AUTOSAR XML (schema 4-2-1)
package /ECUCompositionTypes
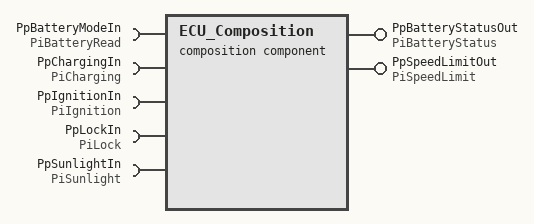
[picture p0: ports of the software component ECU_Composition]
  composition sw component type ECU_Composition
    provide port PpBatteryStatusOut: nonqueued-sender-com-spec=data-element=DeBatteryStatus, provided-interface=PiBatteryStatus
    provide port PpSpeedLimitOut: nonqueued-sender-com-spec=data-element=DeSpeedLimit, provided-interface=PiSpeedLimit
    5 x require port:
      PpBatteryModeIn: required-interface=PiBatteryRead
      PpChargingIn: nonqueued-receiver-com-spec{data-element=DeCharging, filter=data-filter-type=ALWAYS}, required-interface=PiCharging
      PpIgnitionIn: nonqueued-receiver-com-spec{data-element=DeIgnition, filter=data-filter-type=ALWAYS}, required-interface=PiIgnition
      PpLockIn: nonqueued-receiver-com-spec{data-element=DeLock, filter=data-filter-type=ALWAYS}, required-interface=PiLock
      PpSunlightIn: nonqueued-receiver-com-spec{data-element=DeSunlight, filter=data-filter-type=ALWAYS}, required-interface=PiSunlight
    component CpCoApplication: type=CtCoApplication
    delegate CpCoApplication.PpBatteryModeIn <-> outer port PpBatteryModeIn
    delegate CpCoApplication.PpBatteryStatusOut <-> outer port PpBatteryStatusOut
    delegate CpCoApplication.PpChargingIn <-> outer port PpChargingIn
    delegate CpCoApplication.PpIgnitionIn <-> outer port PpIgnitionIn
    delegate CpCoApplication.PpLockIn <-> outer port PpLockIn
    delegate CpCoApplication.PpSpeedLimitOut <-> outer port PpSpeedLimitOut
    delegate CpCoApplication.PpSunlightIn <-> outer port PpSunlightIn
package /EndToEndProtections
  end to end protection set EndToEndConnections
package /VehicleProject
  system System: category=SYSTEM_EXTRACT
    system mapping System_MPPNG
      data-mappings:
        data-element=ECU_Composition.PpLockIn.DeLock, system-signal=sig_Locking
        data-element=ECU_Composition.PpChargingIn.DeCharging, system-signal=sig_SolarPanelSwitch
        data-element=ECU_Composition.PpSunlightIn.DeSunlight, system-signal=sig_SunlightPresence
        data-element=ECU_Composition.PpIgnitionIn.DeIgnition, system-signal=sig_Ignition
        data-element=ECU_Composition.PpBatteryStatusOut.DeBatteryStatus, system-signal=sig_BatteryStatus
        data-element=ECU_Composition.PpSpeedLimitOut.DeSpeedLimit, system-signal=sig_SpeedLimit
    root-software-compositions:
      root sw composition prototype ECU_Composition: software-composition=ECU_Composition
